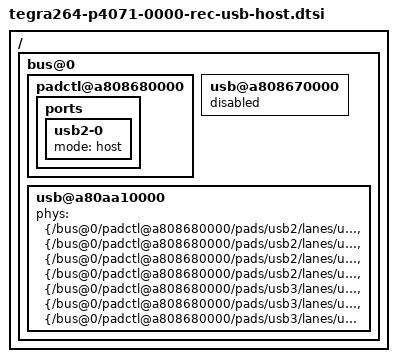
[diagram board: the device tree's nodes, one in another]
// SPDX-License-Identifier: GPL-2.0-only
// SPDX-FileCopyrightText: Copyright (c) 2025, NVIDIA CORPORATION & AFFILIATES.  All rights reserved.

/ {
	bus@0 {
		padctl@a808680000 {
			ports {
				usb2-0 {
					/delete-property/ usb-role-switch;
					/delete-property/ role-switch-default-mode;

					mode = "host";
					status = "okay";
				};
			};
		};

		usb@a808670000 {
			status = "disabled";
		};

		usb@a80aa10000 {
			phys = <&{/bus@0/padctl@a808680000/pads/usb2/lanes/usb2-0}>,
				<&{/bus@0/padctl@a808680000/pads/usb2/lanes/usb2-1}>,
				<&{/bus@0/padctl@a808680000/pads/usb2/lanes/usb2-2}>,
				<&{/bus@0/padctl@a808680000/pads/usb2/lanes/usb2-3}>,
				<&{/bus@0/padctl@a808680000/pads/usb3/lanes/usb3-0}>,
				<&{/bus@0/padctl@a808680000/pads/usb3/lanes/usb3-1}>,
				<&{/bus@0/padctl@a808680000/pads/usb3/lanes/usb3-2}>;
			phy-names = "usb2-0", "usb2-1", "usb2-2", "usb2-3", "usb3-0", "usb3-1", "usb3-2";
			status = "okay";
		};
	};
};
